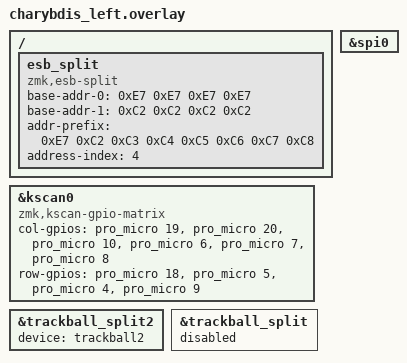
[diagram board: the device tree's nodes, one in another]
#include "charybdis.dtsi"
#include "charybdis_3610.dtsi"
#include "split_input_common.dtsi"

&kscan0 {
	compatible = "zmk,kscan-gpio-matrix";
	
	col-gpios
		= <&pro_micro 19 (GPIO_ACTIVE_HIGH | GPIO_PULL_DOWN)>
		, <&pro_micro 20 (GPIO_ACTIVE_HIGH | GPIO_PULL_DOWN)>
		, <&pro_micro 10 (GPIO_ACTIVE_HIGH | GPIO_PULL_DOWN)>
		, <&pro_micro 6 (GPIO_ACTIVE_HIGH | GPIO_PULL_DOWN)>
		, <&pro_micro 7 (GPIO_ACTIVE_HIGH | GPIO_PULL_DOWN)>
		, <&pro_micro 8 (GPIO_ACTIVE_HIGH | GPIO_PULL_DOWN)>
		;

	row-gpios
		= <&pro_micro 18 GPIO_ACTIVE_HIGH>
		, <&pro_micro 5 GPIO_ACTIVE_HIGH>
		, <&pro_micro 4 GPIO_ACTIVE_HIGH>
		, <&pro_micro 9 GPIO_ACTIVE_HIGH>
		;
};
&spi0 {
    status = "okay";
};
&trackball_split2 {
	device = <&trackball2>;
};
&trackball_split { 
	status = "disabled"; 
};

/{
    esb_split {
        compatible = "zmk,esb-split";
        // These are arbitrary default addresses. In end user products
        // different addresses should be used for each set of devices.
        base-addr-0 = <0xE7 0xE7 0xE7 0xE7>;
        base-addr-1 = <0xC2 0xC2 0xC2 0xC2>;
        addr-prefix = <0xE7 0xC2 0xC3 0xC4 0xC5 0xC6 0xC7 0xC8>;
		 address-index = <4>; // 0xC5
    };
};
